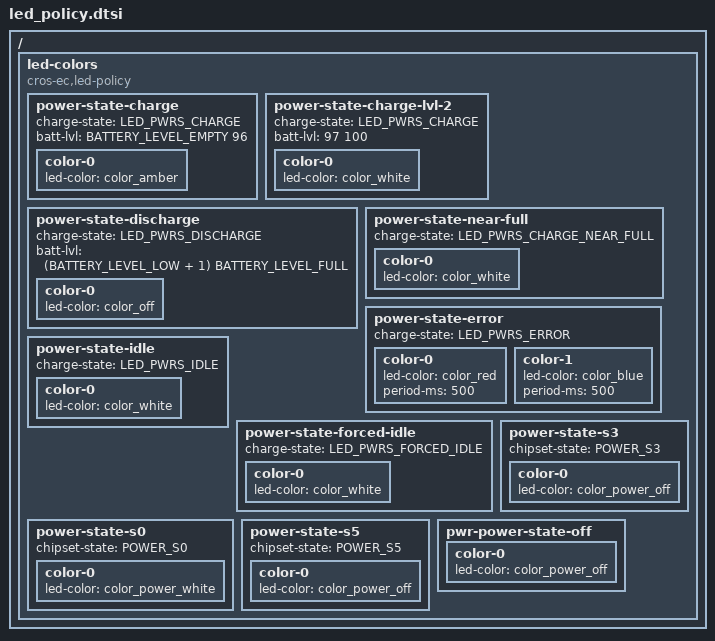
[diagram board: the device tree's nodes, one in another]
#include <dt-bindings/battery.h>

/ {
	led-colors {
		compatible = "cros-ec,led-policy";

		power-state-charge {
			charge-state = "LED_PWRS_CHARGE";
			/* Battery percent range (>= 0, <= 96) */
			batt-lvl = <BATTERY_LEVEL_EMPTY 96>;
			color-0 {
				led-color = <&color_amber>;
			};
		};

		power-state-charge-lvl-2 {
			charge-state = "LED_PWRS_CHARGE";
			/* Battery percent range (>= 97%, <= 100%) */
			batt-lvl = <97 100>;

			color-0 {
				led-color = <&color_white>;
			};
		};

		power-state-discharge {
			charge-state = "LED_PWRS_DISCHARGE";
			/* Battery percent range (>= 11, <= 97) */
			batt-lvl = <(BATTERY_LEVEL_LOW + 1) BATTERY_LEVEL_FULL>;

			color-0 {
				led-color = <&color_off>;
			};
		};

		power-state-near-full {
			charge-state = "LED_PWRS_CHARGE_NEAR_FULL";
			/* Battery percent range (>= 97, <= 100) */

			color-0 {
				led-color = <&color_white>;
			};
		};

		power-state-error {
			charge-state = "LED_PWRS_ERROR";

			color-0 {
				led-color = <&color_red>;
				period-ms = <500>;
			};
			color-1 {
				led-color = <&color_blue>;
				period-ms = <500>;
			};
		};

		power-state-idle {
			charge-state = "LED_PWRS_IDLE";

			color-0 {
				led-color = <&color_white>;
			};
		};

		power-state-forced-idle {
			charge-state = "LED_PWRS_FORCED_IDLE";

			color-0 {
				led-color = <&color_white>;
			};
		};

		power-state-s0 {
			chipset-state = "POWER_S0";

			color-0 {
				led-color = <&color_power_white>;
			};
		};

		power-state-s3 {
			chipset-state = "POWER_S3";

			color-0 {
				led-color = <&color_power_off>;
			};
		};

		power-state-s5 {
			chipset-state = "POWER_S5";

			color-0 {
				led-color = <&color_power_off>;
			};
		};
		
		pwr-power-state-off {
			color-0 {
				led-color = <&color_power_off>;
			};
		};
	};
};
